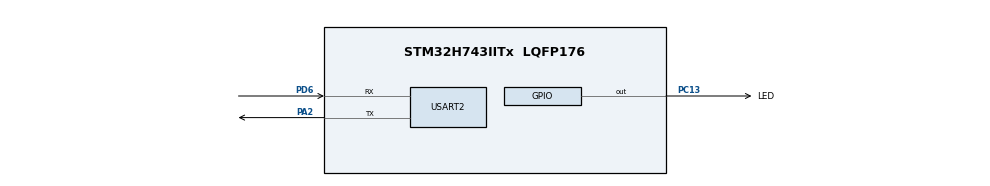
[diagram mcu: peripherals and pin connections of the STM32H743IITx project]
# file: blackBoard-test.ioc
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CORTEX_M7.default_mode_Activation=1
Mcu.Family=STM32H7
Mcu.Name=STM32H743IITx
Mcu.Package=LQFP176
NVIC.PriorityGroup=NVIC_PRIORITYGROUP_4
NVIC.USART2_IRQn=true\:0\:0\:false\:false\:true\:true\:true\:true
PA10.Signal=USART1_RX
PA13\ (JTMS/SWDIO).Mode=Serial_Wire
PA13\ (JTMS/SWDIO).Signal=DEBUG_JTMS-SWDIO
PA14\ (JTCK/SWCLK).Mode=Serial_Wire
PA14\ (JTCK/SWCLK).Signal=DEBUG_JTCK-SWCLK
PA2.Mode=Asynchronous
PA2.Signal=USART2_TX
PA9.Signal=USART1_TX
PC13.GPIO_Label=LED
PC13.PinState=GPIO_PIN_SET
PC13.Signal=GPIO_Output
PD6.Mode=Asynchronous
PD6.Signal=USART2_RX
ProjectManager.HeapSize=0x200
ProjectManager.StackSize=0x400
ProjectManager.TargetToolchain=STM32CubeIDE
RCC.ADCFreq_Value=129000000
RCC.APB1Freq_Value=120000000
RCC.APB2Freq_Value=120000000
RCC.APB3Freq_Value=120000000
RCC.APB4Freq_Value=120000000
RCC.CortexFreq_Value=480000000
RCC.D1PPRE=RCC_APB3_DIV2
RCC.D2PPRE1=RCC_APB1_DIV2
RCC.D2PPRE2=RCC_APB2_DIV2
RCC.D3PPRE=RCC_APB4_DIV2
RCC.DIVM1=4
RCC.DIVN1=60
RCC.HCLKFreq_Value=240000000
RCC.HPRE=RCC_HCLK_DIV2
RCC.PLL2FRACN=0
RCC.PLL3FRACN=0
RCC.PLLFRACN=0
RCC.SYSCLKFreq_VALUE=480000000
RCC.SYSCLKSource=RCC_SYSCLKSOURCE_PLLCLK
RCC.USBFreq_Value=480000000
USART2.VirtualMode-Asynchronous=VM_ASYNC
VP_MEMORYMAP_VS_MEMORYMAP.Mode=CurAppReg
board=custom

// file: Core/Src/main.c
/* USER CODE BEGIN Header */
/**
  ******************************************************************************
  * @file           : main.c
  * @brief          : Main program body
  ******************************************************************************
  * @attention
  *
  * Copyright (c) 2025 STMicroelectronics.
  * All rights reserved.
  *
  * This software is licensed under terms that can be found in the LICENSE file
  * in the root directory of this software component.
  * If no LICENSE file comes with this software, it is provided AS-IS.
  *
  ******************************************************************************
  */
/* USER CODE END Header */
#include "main.h"

/* USER CODE BEGIN Includes */
#include <string.h>
#include "dataLink.h"
#include "nodeSort.h"
#include "process.h"

/* USER CODE END Includes */

UART_HandleTypeDef huart2;

/* USER CODE BEGIN PV */
dataLink link;
pipeDef ioPipe;

#define UART_BUFFER_SIZE 128

uint8_t rxRecieve[2];
uint8_t rxBuffer[UART_BUFFER_SIZE];

uint8_t order[MAX_NODES];

float in0[VECTOR_SIZE] = {2,4,6,8,10,12,14,16};
float in1[VECTOR_SIZE] = {8,7,6,5,4,3,2,1};
float out0[VECTOR_SIZE], out1[VECTOR_SIZE];
float out2[VECTOR_SIZE], out3[VECTOR_SIZE];

uint8_t uartRxIndex = 0;
/* USER CODE END PV */

void SystemClock_Config(void);
static void MPU_Config(void);
static void MX_GPIO_Init(void);
static void MX_USART2_UART_Init(void);

/* USER CODE BEGIN 0 */
uint32_t test = 0;

void HAL_UART_RxCpltCallback(UART_HandleTypeDef *huart)
{

	if (huart == &huart2)
	{
		char received = rxRecieve[0];

		link.readUART(&link, received);

		rxBuffer[uartRxIndex++] = received;
		if (uartRxIndex >= UART_BUFFER_SIZE) uartRxIndex = 0;

		HAL_UART_Receive_IT(&huart2, rxRecieve, 1);
	}

	/*
	rxBuffer[uartRxIndex] = rxRecieve[0];
	if (uartRxIndex++ >= UART_BUFFER_SIZE)
	{
		uartRxIndex = 0;
	}

	HAL_UART_Receive_IT(&huart2, rxRecieve, 1);
	*/
}

/* USER CODE END 0 */

int main(void)
{

  /* MPU Configuration--------------------------------------------------------*/
  MPU_Config();

  /* MCU Configuration--------------------------------------------------------*/

  /* Reset of all peripherals, Initializes the Flash interface and the Systick. */
  HAL_Init();

  /* Configure the system clock */
  SystemClock_Config();

  /* Initialize all configured peripherals */
  MX_GPIO_Init();
  MX_USART2_UART_Init();
  /* USER CODE BEGIN 2 */
  initDataLink(&link);
  HAL_UART_Receive_IT(&huart2, rxRecieve, 1);
  /* USER CODE END 2 */

  /* Infinite loop */
  while (1)
  {

    /* USER CODE BEGIN 3 */
	 /* test++;
	  if (test >= 4800000)
	  {
		  test = 0;
		  HAL_GPIO_TogglePin(LED_GPIO_Port, LED_Pin);
	  }*/
	  __WFI();
	  topoSort(&link, &order);

  }
  /* USER CODE END 3 */
}

void SystemClock_Config(void)
{
  RCC_OscInitTypeDef RCC_OscInitStruct = {0};
  RCC_ClkInitTypeDef RCC_ClkInitStruct = {0};

  /** Supply configuration update enable
  */
  HAL_PWREx_ConfigSupply(PWR_LDO_SUPPLY);

  /** Configure the main internal regulator output voltage
  */
  __HAL_PWR_VOLTAGESCALING_CONFIG(PWR_REGULATOR_VOLTAGE_SCALE0);

  while(!__HAL_PWR_GET_FLAG(PWR_FLAG_VOSRDY)) {}

  /** Initializes the RCC Oscillators according to the specified parameters
  * in the RCC_OscInitTypeDef structure.
  */
  RCC_OscInitStruct.OscillatorType = RCC_OSCILLATORTYPE_HSI;
  RCC_OscInitStruct.HSIState = RCC_HSI_DIV1;
  RCC_OscInitStruct.HSICalibrationValue = RCC_HSICALIBRATION_DEFAULT;
  RCC_OscInitStruct.PLL.PLLState = RCC_PLL_ON;
  RCC_OscInitStruct.PLL.PLLSource = RCC_PLLSOURCE_HSI;
  RCC_OscInitStruct.PLL.PLLM = 4;
  RCC_OscInitStruct.PLL.PLLN = 60;
  RCC_OscInitStruct.PLL.PLLP = 2;
  RCC_OscInitStruct.PLL.PLLQ = 2;
  RCC_OscInitStruct.PLL.PLLR = 2;
  RCC_OscInitStruct.PLL.PLLRGE = RCC_PLL1VCIRANGE_3;
  RCC_OscInitStruct.PLL.PLLVCOSEL = RCC_PLL1VCOWIDE;
  RCC_OscInitStruct.PLL.PLLFRACN = 0;
  if (HAL_RCC_OscConfig(&RCC_OscInitStruct) != HAL_OK)
  {
    Error_Handler();
  }

  /** Initializes the CPU, AHB and APB buses clocks
  */
  RCC_ClkInitStruct.ClockType = RCC_CLOCKTYPE_HCLK|RCC_CLOCKTYPE_SYSCLK
                              |RCC_CLOCKTYPE_PCLK1|RCC_CLOCKTYPE_PCLK2
                              |RCC_CLOCKTYPE_D3PCLK1|RCC_CLOCKTYPE_D1PCLK1;
  RCC_ClkInitStruct.SYSCLKSource = RCC_SYSCLKSOURCE_PLLCLK;
  RCC_ClkInitStruct.SYSCLKDivider = RCC_SYSCLK_DIV1;
  RCC_ClkInitStruct.AHBCLKDivider = RCC_HCLK_DIV2;
  RCC_ClkInitStruct.APB3CLKDivider = RCC_APB3_DIV2;
  RCC_ClkInitStruct.APB1CLKDivider = RCC_APB1_DIV2;
  RCC_ClkInitStruct.APB2CLKDivider = RCC_APB2_DIV2;
  RCC_ClkInitStruct.APB4CLKDivider = RCC_APB4_DIV2;

  if (HAL_RCC_ClockConfig(&RCC_ClkInitStruct, FLASH_LATENCY_4) != HAL_OK)
  {
    Error_Handler();
  }
}

static void MX_USART2_UART_Init(void)
{

  huart2.Instance = USART2;
  huart2.Init.BaudRate = 115200;
  huart2.Init.WordLength = UART_WORDLENGTH_8B;
  huart2.Init.StopBits = UART_STOPBITS_1;
  huart2.Init.Parity = UART_PARITY_NONE;
  huart2.Init.Mode = UART_MODE_TX_RX;
  huart2.Init.HwFlowCtl = UART_HWCONTROL_NONE;
  huart2.Init.OverSampling = UART_OVERSAMPLING_16;
  huart2.Init.OneBitSampling = UART_ONE_BIT_SAMPLE_DISABLE;
  huart2.Init.ClockPrescaler = UART_PRESCALER_DIV1;
  huart2.AdvancedInit.AdvFeatureInit = UART_ADVFEATURE_NO_INIT;
  if (HAL_UART_Init(&huart2) != HAL_OK)
  {
    Error_Handler();
  }
  if (HAL_UARTEx_SetTxFifoThreshold(&huart2, UART_TXFIFO_THRESHOLD_1_8) != HAL_OK)
  {
    Error_Handler();
  }
  if (HAL_UARTEx_SetRxFifoThreshold(&huart2, UART_RXFIFO_THRESHOLD_1_8) != HAL_OK)
  {
    Error_Handler();
  }
  if (HAL_UARTEx_DisableFifoMode(&huart2) != HAL_OK)
  {
    Error_Handler();
  }

}

static void MX_GPIO_Init(void)
{
  GPIO_InitTypeDef GPIO_InitStruct = {0};

  /* GPIO Ports Clock Enable */
  __HAL_RCC_GPIOC_CLK_ENABLE();
  __HAL_RCC_GPIOA_CLK_ENABLE();
  __HAL_RCC_GPIOD_CLK_ENABLE();

  /*Configure GPIO pin Output Level */
  HAL_GPIO_WritePin(LED_GPIO_Port, LED_Pin, GPIO_PIN_SET);

  /*Configure GPIO pin : LED_Pin */
  GPIO_InitStruct.Pin = LED_Pin;
  GPIO_InitStruct.Mode = GPIO_MODE_OUTPUT_PP;
  GPIO_InitStruct.Pull = GPIO_NOPULL;
  GPIO_InitStruct.Speed = GPIO_SPEED_FREQ_LOW;
  HAL_GPIO_Init(LED_GPIO_Port, &GPIO_InitStruct);

  /*Configure GPIO pins : PA9 PA10 */
  GPIO_InitStruct.Pin = GPIO_PIN_9|GPIO_PIN_10;
  GPIO_InitStruct.Mode = GPIO_MODE_AF_PP;
  GPIO_InitStruct.Pull = GPIO_NOPULL;
  GPIO_InitStruct.Speed = GPIO_SPEED_FREQ_LOW;
  GPIO_InitStruct.Alternate = GPIO_AF7_USART1;
  HAL_GPIO_Init(GPIOA, &GPIO_InitStruct);

}

 /* MPU Configuration */

void MPU_Config(void)
{
  MPU_Region_InitTypeDef MPU_InitStruct = {0};

  /* Disables the MPU */
  HAL_MPU_Disable();

  /** Initializes and configures the Region and the memory to be protected
  */
  MPU_InitStruct.Enable = MPU_REGION_ENABLE;
  MPU_InitStruct.Number = MPU_REGION_NUMBER0;
  MPU_InitStruct.BaseAddress = 0x0;
  MPU_InitStruct.Size = MPU_REGION_SIZE_4GB;
  MPU_InitStruct.SubRegionDisable = 0x87;
  MPU_InitStruct.TypeExtField = MPU_TEX_LEVEL0;
  MPU_InitStruct.AccessPermission = MPU_REGION_NO_ACCESS;
  MPU_InitStruct.DisableExec = MPU_INSTRUCTION_ACCESS_DISABLE;
  MPU_InitStruct.IsShareable = MPU_ACCESS_SHAREABLE;
  MPU_InitStruct.IsCacheable = MPU_ACCESS_NOT_CACHEABLE;
  MPU_InitStruct.IsBufferable = MPU_ACCESS_NOT_BUFFERABLE;

  HAL_MPU_ConfigRegion(&MPU_InitStruct);
  /* Enables the MPU */
  HAL_MPU_Enable(MPU_PRIVILEGED_DEFAULT);

}

void Error_Handler(void)
{
  __disable_irq();
  while (1)
  {
  }
}
